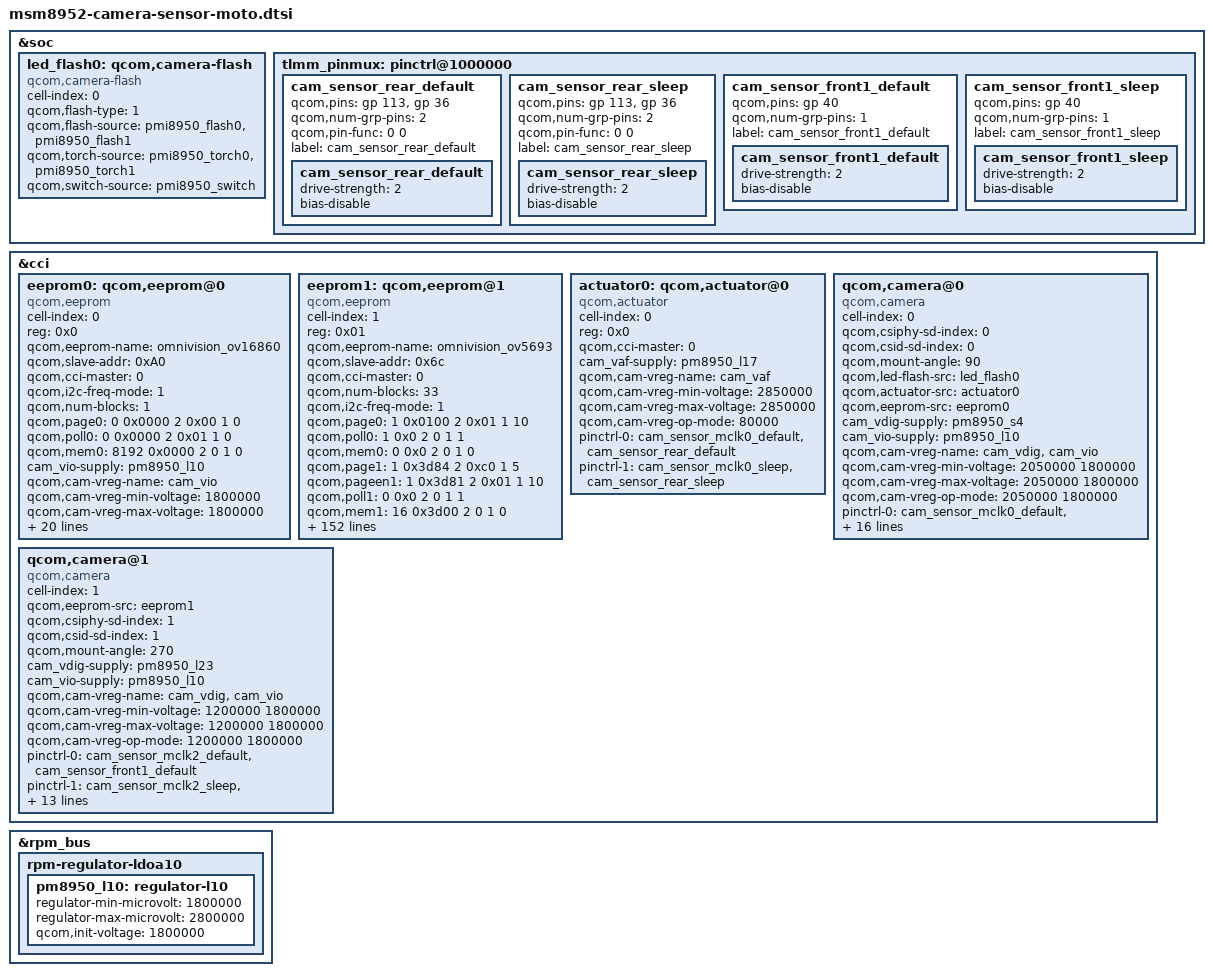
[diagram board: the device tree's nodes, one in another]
/*
 * Copyright (c) 2015, The Linux Foundation. All rights reserved.
 *
 * This program is free software; you can redistribute it and/or modify
 * it under the terms of the GNU General Public License version 2 and
 * only version 2 as published by the Free Software Foundation.
 *
 * This program is distributed in the hope that it will be useful,
 * but WITHOUT ANY WARRANTY; without even the implied warranty of
 * MERCHANTABILITY or FITNESS FOR A PARTICULAR PURPOSE.  See the
 * GNU General Public License for more details.
 */

&soc {
	led_flash0: qcom,camera-flash {
		cell-index = <0>;
		compatible = "qcom,camera-flash";
		qcom,flash-type = <1>;
		qcom,flash-source = <&pmi8950_flash0 &pmi8950_flash1>;
		qcom,torch-source = <&pmi8950_torch0 &pmi8950_torch1>;
		qcom,switch-source = <&pmi8950_switch>;
	};
};

&cci {
	/* OV16860 EEPROM */
	eeprom0: qcom,eeprom@0 {
		cell-index = <0>;
		reg = <0x0>;
		qcom,eeprom-name = "omnivision_ov16860";
		compatible = "qcom,eeprom";
		qcom,slave-addr = <0xA0>;
		qcom,cci-master = <0>;
		qcom,i2c-freq-mode = <1>;
		qcom,num-blocks = <1>;
		qcom,page0 = <0 0x0000 2 0x00 1 0>;
		qcom,poll0 = <0 0x0000 2 0x01 1 0>;
		qcom,mem0 = <8192 0x0000 2 0 1 0>;

		cam_vio-supply = <&pm8950_l10>;
		qcom,cam-vreg-name = "cam_vio";
		qcom,cam-vreg-min-voltage = <1800000> ;
		qcom,cam-vreg-max-voltage = <1800000>;
		qcom,cam-vreg-op-mode = <1800000>;
		qcom,gpio-no-mux = <0>;

		qcom,cam-power-seq-type = "sensor_vreg";
		qcom,cam-power-seq-val = "cam_vio";
		qcom,cam-power-seq-cfg-val = <1>;
		qcom,cam-power-seq-delay = <3>;

		pinctrl-names = "cam_default", "cam_suspend";
		pinctrl-0 = <&cam_sensor_mclk0_default
			     &cam_sensor_rear_default>;
		pinctrl-1 = <&cam_sensor_mclk0_sleep &cam_sensor_rear_sleep>;
		gpios = <&msm_gpio 26 0>,
			<&msm_gpio 36 0>,
			<&msm_gpio 113 0>;
		qcom,gpio-reset = <1>;
		qcom,gpio-vdig = <2>;
		qcom,gpio-req-tbl-num = <0 1 2>;
		qcom,gpio-req-tbl-flags = <1 0 0>;
		qcom,gpio-req-tbl-label = "CAMIF_MCLK0",
					  "CAM_RESET0",
					  "CAM_VDIG0";
		clocks = <&clock_gcc clk_mclk0_clk_src>,
			 <&clock_gcc clk_gcc_camss_mclk0_clk>;
		clock-names = "cam_src_clk", "cam_clk";
		qcom,clock-rates = <24000000 0>;
		status = "ok";
	};

	/* OV5693 OTP */
	eeprom1: qcom,eeprom@1 {
		cell-index = <1>;
		reg = <0x01>;
		qcom,eeprom-name = "omnivision_ov5693";
		compatible = "qcom,eeprom";
		qcom,slave-addr = <0x6c>;
		qcom,cci-master = <0>;
		qcom,num-blocks = <33>;
		qcom,i2c-freq-mode = <1>;

		/* Stream ON */
		qcom,page0 = <1 0x0100 2 0x01 1 10>;
		qcom,poll0 = <1 0x0 2 0 1 1>;
		qcom,mem0 = <0 0x0 2 0 1 0>;

		/* Now read otp */
		qcom,page1 = <1 0x3d84 2 0xc0 1 5>;
		qcom,pageen1 = <1 0x3d81 2 0x01 1 10>;
		qcom,poll1 = <0 0x0 2 0 1 1>;
		qcom,mem1 = <16 0x3d00 2 0 1 0>;

		qcom,page2 = <1 0x3d84 2 0xc1 1 5>;
		qcom,pageen2 = <1 0x3d81 2 0x01 1 10>;
		qcom,poll2 = <0 0x0 2 0 1 1>;
		qcom,mem2 = <16 0x3d00 2 0 1 0>;

		qcom,page3 = <1 0x3d84 2 0xc2 1 5>;
		qcom,pageen3 = <1 0x3d81 2 0x01 1 10>;
		qcom,poll3 = <0 0x0 2 0 1 1>;
		qcom,mem3 = <16 0x3d00 2 0 1 0>;

		qcom,page4 = <1 0x3d84 2 0xc3 1 5>;
		qcom,pageen4 = <1 0x3d81 2 0x01 1 10>;
		qcom,poll4 = <0 0x0 2 0 1 1>;
		qcom,mem4 = <16 0x3d00 2 0 1 0>;

		qcom,page5 = <1 0x3d84 2 0xc4 1 5>;
		qcom,pageen5 = <1 0x3d81 2 0x01 1 10>;
		qcom,poll5 = <0 0x0 2 0 1 1>;
		qcom,mem5 = <16 0x3d00 2 0 1 0>;

		qcom,page6 = <1 0x3d84 2 0xc5 1 5>;
		qcom,pageen6 = <1 0x3d81 2 0x01 1 10>;
		qcom,poll6 = <0 0x0 2 0 1 1>;
		qcom,mem6 = <16 0x3d00 2 0 1 0>;

		qcom,page7 = <1 0x3d84 2 0xc6 1 5>;
		qcom,pageen7 = <1 0x3d81 2 0x01 1 10>;
		qcom,poll7 = <0 0x0 2 0 1 1>;
		qcom,mem7 = <16 0x3d00 2 0 1 0>;

		qcom,page8 = <1 0x3d84 2 0xc7 1 5>;
		qcom,pageen8 = <1 0x3d81 2 0x01 1 10>;
		qcom,poll8 = <0 0x0 2 0 1 1>;
		qcom,mem8 = <16 0x3d00 2 0 1 0>;

		qcom,page9 = <1 0x3d84 2 0xc8 1 5>;
		qcom,pageen9 = <1 0x3d81 2 0x01 1 10>;
		qcom,poll9 = <0 0x0 2 0 1 1>;
		qcom,mem9 = <16 0x3d00 2 0 1 0>;

		qcom,page10 = <1 0x3d84 2 0xc9 1 5>;
		qcom,pageen10 = <1 0x3d81 2 0x01 1 10>;
		qcom,poll10 = <0 0x0 2 0 1 1>;
		qcom,mem10 = <16 0x3d00 2 0 1 0>;

		qcom,page11 = <1 0x3d84 2 0xca 1 5>;
		qcom,pageen11 = <1 0x3d81 2 0x01 1 10>;
		qcom,poll11 = <0 0x0 2 0 1 1>;
		qcom,mem11 = <16 0x3d00 2 0 1 0>;

		qcom,page12 = <1 0x3d84 2 0xcb 1 5>;
		qcom,pageen12 = <1 0x3d81 2 0x01 1 10>;
		qcom,poll12 = <0 0x0 2 0 1 1>;
		qcom,mem12 = <16 0x3d00 2 0 1 0>;

		qcom,page13 = <1 0x3d84 2 0xcc 1 5>;
		qcom,pageen13 = <1 0x3d81 2 0x01 1 10>;
		qcom,poll13 = <0 0x0 2 0 1 1>;
		qcom,mem13 = <16 0x3d00 2 0 1 0>;

		qcom,page14 = <1 0x3d84 2 0xcd 1 5>;
		qcom,pageen14 = <1 0x3d81 2 0x01 1 10>;
		qcom,poll14 = <0 0x0 2 0 1 1>;
		qcom,mem14 = <16 0x3d00 2 0 1 0>;

		qcom,page15 = <1 0x3d84 2 0xce 1 5>;
		qcom,pageen15 = <1 0x3d81 2 0x01 1 10>;
		qcom,poll15 = <0 0x0 2 0 1 1>;
		qcom,mem15 = <16 0x3d00 2 0 1 0>;

		qcom,page16 = <1 0x3d84 2 0xcf 1 5>;
		qcom,pageen16 = <1 0x3d81 2 0x01 1 10>;
		qcom,poll16 = <0 0x0 2 0 1 1>;
		qcom,mem16 = <16 0x3d00 2 0 1 0>;

		qcom,page17 = <1 0x3d84 2 0xd0 1 5>;
		qcom,pageen17 = <1 0x3d81 2 0x01 1 10>;
		qcom,poll17 = <0 0x0 2 0 1 1>;
		qcom,mem17 = <16 0x3d00 2 0 1 0>;

		qcom,page18 = <1 0x3d84 2 0xd1 1 5>;
		qcom,pageen18 = <1 0x3d81 2 0x01 1 10>;
		qcom,poll18 = <0 0x0 2 0 1 1>;
		qcom,mem18 = <16 0x3d00 2 0 1 0>;

		qcom,page19 = <1 0x3d84 2 0xd2 1 5>;
		qcom,pageen19 = <1 0x3d81 2 0x01 1 10>;
		qcom,poll19 = <0 0x0 2 0 1 1>;
		qcom,mem19 = <16 0x3d00 2 0 1 0>;

		qcom,page20 = <1 0x3d84 2 0xd3 1 5>;
		qcom,pageen20 = <1 0x3d81 2 0x01 1 10>;
		qcom,poll20 = <0 0x0 2 0 1 1>;
		qcom,mem20 = <16 0x3d00 2 0 1 0>;

		qcom,page21 = <1 0x3d84 2 0xd4 1 5>;
		qcom,pageen21 = <1 0x3d81 2 0x01 1 10>;
		qcom,poll21 = <0 0x0 2 0 1 1>;
		qcom,mem21 = <16 0x3d00 2 0 1 0>;

		qcom,page22 = <1 0x3d84 2 0xd5 1 5>;
		qcom,pageen22 = <1 0x3d81 2 0x01 1 10>;
		qcom,poll22 = <0 0x0 2 0 1 1>;
		qcom,mem22 = <16 0x3d00 2 0 1 0>;

		qcom,page23 = <1 0x3d84 2 0xd6 1 5>;
		qcom,pageen23 = <1 0x3d81 2 0x01 1 10>;
		qcom,poll23 = <0 0x0 2 0 1 1>;
		qcom,mem23 = <16 0x3d00 2 0 1 0>;

		qcom,page24 = <1 0x3d84 2 0xd7 1 5>;
		qcom,pageen24 = <1 0x3d81 2 0x01 1 10>;
		qcom,poll24 = <0 0x0 2 0 1 1>;
		qcom,mem24 = <16 0x3d00 2 0 1 0>;

		qcom,page25 = <1 0x3d84 2 0xd8 1 5>;
		qcom,pageen25 = <1 0x3d81 2 0x01 1 10>;
		qcom,poll25 = <0 0x0 2 0 1 1>;
		qcom,mem25 = <16 0x3d00 2 0 1 0>;

		qcom,page26 = <1 0x3d84 2 0xd9 1 5>;
		qcom,pageen26 = <1 0x3d81 2 0x01 1 10>;
		qcom,poll26 = <0 0x0 2 0 1 1>;
		qcom,mem26 = <16 0x3d00 2 0 1 0>;

		qcom,page27 = <1 0x3d84 2 0xda 1 5>;
		qcom,pageen27 = <1 0x3d81 2 0x01 1 10>;
		qcom,poll27 = <0 0x0 2 0 1 1>;
		qcom,mem27 = <16 0x3d00 2 0 1 0>;

		qcom,page28 = <1 0x3d84 2 0xdb 1 5>;
		qcom,pageen28 = <1 0x3d81 2 0x01 1 10>;
		qcom,poll28 = <0 0x0 2 0 1 1>;
		qcom,mem28 = <16 0x3d00 2 0 1 0>;

		qcom,page29 = <1 0x3d84 2 0xdc 1 5>;
		qcom,pageen29 = <1 0x3d81 2 0x01 1 10>;
		qcom,poll29 = <0 0x0 2 0 1 1>;
		qcom,mem29 = <16 0x3d00 2 0 1 0>;

		qcom,page30 = <1 0x3d84 2 0xdd 1 5>;
		qcom,pageen30 = <1 0x3d81 2 0x01 1 10>;
		qcom,poll30 = <0 0x0 2 0 1 1>;
		qcom,mem30 = <16 0x3d00 2 0 1 0>;

		qcom,page31 = <1 0x3d84 2 0xde 1 5>;
		qcom,pageen31 = <1 0x3d81 2 0x01 1 10>;
		qcom,poll31 = <0 0x0 2 0 1 1>;
		qcom,mem31 = <16 0x3d00 2 0 1 0>;

		qcom,page32 = <1 0x3d84 2 0xdf 1 5>;
		qcom,pageen32 = <1 0x3d81 2 0x01 1 10>;
		qcom,poll32 = <0 0x0 2 0 1 1>;
		qcom,mem32 = <16 0x3d00 2 0 1 0>;

		cam_vdig-supply = <&pm8950_l23>;
		cam_vio-supply = <&pm8950_l10>;
		qcom,cam-vreg-name = "cam_vdig", "cam_vio";
		qcom,cam-vreg-min-voltage = <1200000 1800000>;
		qcom,cam-vreg-max-voltage = <1200000 1800000>;
		qcom,cam-vreg-op-mode = <1200000 1800000>;
		qcom,gpio-no-mux = <0>;
		pinctrl-names = "cam_default", "cam_suspend";
		pinctrl-0 = <&cam_sensor_mclk2_default
			&cam_sensor_front1_default>;
		pinctrl-1 = <&cam_sensor_mclk2_sleep
			&cam_sensor_front1_sleep>;
		gpios = <&msm_gpio 28 0>,
			<&msm_gpio 40 0>;
		qcom,gpio-reset = <1>;
		qcom,gpio-req-tbl-num = <0 1>;
		qcom,gpio-req-tbl-flags = <1 0>;
		qcom,gpio-req-tbl-label = "CAMIF_MCLK2",
					  "CAM_RESET2";
		clocks = <&clock_gcc clk_mclk2_clk_src>,
				<&clock_gcc clk_gcc_camss_mclk2_clk>;
		clock-names = "cam_src_clk", "cam_clk";
		qcom,clock-rates = <24000000 0>;
		qcom,cam-power-seq-type = "sensor_gpio", "sensor_vreg",
			"sensor_vreg", "sensor_gpio", "sensor_clk";
		qcom,cam-power-seq-val = "sensor_gpio_reset", "cam_vio",
			"cam_vdig", "sensor_gpio_reset", "sensor_cam_mclk";
		qcom,cam-power-seq-cfg-val = <0 0 0 1 24000000>;
		qcom,cam-power-seq-delay = <1 1 1 30 20>;

		status = "ok";
	};

	actuator0: qcom,actuator@0 {
		cell-index = <0>;
		reg = <0x0>;
		compatible = "qcom,actuator";
		qcom,cci-master = <0>;
		cam_vaf-supply = <&pm8950_l17>;
		qcom,cam-vreg-name = "cam_vaf";
		qcom,cam-vreg-min-voltage = <2850000>;
		qcom,cam-vreg-max-voltage = <2850000>;
		qcom,cam-vreg-op-mode = <80000>;
		pinctrl-names = "cam_default", "cam_suspend";
		pinctrl-0 = <&cam_sensor_mclk0_default
			     &cam_sensor_rear_default>;
		pinctrl-1 = <&cam_sensor_mclk0_sleep &cam_sensor_rear_sleep>;
	};

	qcom,camera@0 {
		cell-index = <0>;
		compatible = "qcom,camera";
		qcom,csiphy-sd-index = <0>;
		qcom,csid-sd-index = <0>;
		qcom,mount-angle = <90>;
		qcom,led-flash-src = <&led_flash0>;
		qcom,actuator-src = <&actuator0>;
		qcom,eeprom-src = <&eeprom0>;
		cam_vdig-supply = <&pm8950_s4>;
		cam_vio-supply = <&pm8950_l10>;
		qcom,cam-vreg-name = "cam_vdig", "cam_vio";
		/* camera needs s4 regulator min 1.85v but audio
		 * 8952_wcd_codec uses same regulator at min 2.05v */
		qcom,cam-vreg-min-voltage = <2050000 1800000> ;
		qcom,cam-vreg-max-voltage = <2050000 1800000>;
		qcom,cam-vreg-op-mode = <2050000 1800000>;
		pinctrl-names = "cam_default", "cam_suspend";
		pinctrl-0 = <&cam_sensor_mclk0_default
			     &cam_sensor_rear_default>;
		pinctrl-1 = <&cam_sensor_mclk0_sleep &cam_sensor_rear_sleep>;
		gpios = <&msm_gpio 26 0>,
			<&msm_gpio 36 0>,
			<&msm_gpio 113 0>;
		qcom,gpio-reset = <1>;
		qcom,gpio-vdig = <2>;
		qcom,gpio-req-tbl-num = <0 1 2>;
		qcom,gpio-req-tbl-flags = <1 0 0>;
		qcom,gpio-req-tbl-label = "CAMIF_MCLK0",
					  "CAM_RESET0",
					  "CAM_VDIG0";
		qcom,sensor-position = <0>;
		qcom,sensor-mode = <0>;
		qcom,cci-master = <0>;
		status = "ok";
		clocks = <&clock_gcc clk_mclk0_clk_src>,
			 <&clock_gcc clk_gcc_camss_mclk0_clk>;
		clock-names = "cam_src_clk", "cam_clk";
		qcom,clock-rates = <24000000 0>;
	};

	qcom,camera@1 {
		cell-index = <1>;
		compatible = "qcom,camera";
		qcom,eeprom-src = <&eeprom1>;
		qcom,csiphy-sd-index = <1>;
		qcom,csid-sd-index = <1>;
		qcom,mount-angle = <270>;
		cam_vdig-supply = <&pm8950_l23>;
		cam_vio-supply = <&pm8950_l10>;
		qcom,cam-vreg-name = "cam_vdig", "cam_vio";
		qcom,cam-vreg-min-voltage = <1200000 1800000>;
		qcom,cam-vreg-max-voltage = <1200000 1800000>;
		qcom,cam-vreg-op-mode = <1200000 1800000>;
		pinctrl-names = "cam_default", "cam_suspend";

		pinctrl-0 = <&cam_sensor_mclk2_default
			&cam_sensor_front1_default>;
		pinctrl-1 = <&cam_sensor_mclk2_sleep
			&cam_sensor_front1_sleep>;

		gpios = <&msm_gpio 28 0>,
			<&msm_gpio 40 0>;
		qcom,gpio-reset = <1>;
		qcom,gpio-req-tbl-num = <0 1>;
		qcom,gpio-req-tbl-flags = <1 0>;
		qcom,gpio-req-tbl-label = "CAMIF_MCLK2",
					"CAM_RESET2";
		qcom,sensor-position = <1>;
		qcom,sensor-mode = <0>;
		qcom,cci-master = <0>;
		status = "ok";
		clocks = <&clock_gcc clk_mclk2_clk_src>,
				<&clock_gcc clk_gcc_camss_mclk2_clk>;
		clock-names = "cam_src_clk", "cam_clk";
		qcom,clock-rates = <24000000 0>;
	};
};

&soc {
	tlmm_pinmux: pinctrl@1000000 {
		/delete-node/ cam_sensor_rear_default;
		/delete-node/ cam_sensor_rear_sleep;

		cam_sensor_rear_default {
			/* VDIG, RESET */
			qcom,pins = <&gp 113>, <&gp 36>;
			qcom,num-grp-pins = <2>;
			qcom,pin-func = <0 0>;
			label = "cam_sensor_rear_default";
			/* active state */
			cam_sensor_rear_default: cam_sensor_rear_default {
				drive-strength = <2>; /* 2 MA */
				bias-disable; /* No PULL */
			};
		};

		cam_sensor_rear_sleep {
			/* VDIG, RESET */
			qcom,pins = <&gp 113>, <&gp 36>;
			qcom,num-grp-pins = <2>;
			qcom,pin-func = <0 0>;
			label = "cam_sensor_rear_sleep";
			/* active state */
			cam_sensor_rear_sleep: cam_sensor_rear_sleep {
				drive-strength = <2>; /* 2 MA */
				bias-disable; /* No PULL */
			};
		};

		cam_sensor_front1_default {
			/* RESET */
			qcom,pins = <&gp 40>;
			qcom,num-grp-pins = <1>;
			label = "cam_sensor_front1_default";
			/* active state */
			cam_sensor_front1_default: cam_sensor_front1_default {
				drive-strength = <2>; /* 2 MA */
				bias-disable; /* No PULL */
			};
		};

		cam_sensor_front1_sleep {
			/* RESET */
			qcom,pins = <&gp 40>;
			qcom,num-grp-pins = <1>;
			label = "cam_sensor_front1_sleep";
			/*suspended state */
			cam_sensor_front1_sleep: cam_sensor_front1_sleep {
				drive-strength = <2>; /* 2 MA */
				bias-disable; /* No PULL */
			};
		};
	};
};

&rpm_bus {
	rpm-regulator-ldoa10 {
		status = "okay";
		pm8950_l10: regulator-l10 {
			regulator-min-microvolt = <1800000>;
			regulator-max-microvolt = <2800000>;
			qcom,init-voltage = <1800000>;
			status = "okay";
		};
	};
};
